AUTOSAR XML (schema 4-2-1)
package /ComponentTypes
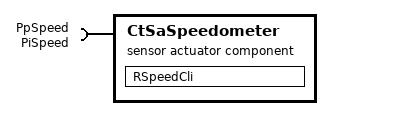
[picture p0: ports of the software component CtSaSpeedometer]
  sensor actuator sw component type CtSaSpeedometer
    require port PpSpeed: required-interface=PiSpeed
    behavior CtSaSpeedometer_InternalBehavior: data-type-mapping=ApMappingSet
      runnable RSpeedCli
        sync call SC_PpSpeed_ReadChannel: operation=PpSpeed.ReadChannel, timeout=0
  swc implementation CtSaSpeedometer_Implementation: behavior=CtSaSpeedometer_InternalBehavior
    code-descriptors:
      code Default: artifact-descriptors=autosar-engineering-object={short-label=Default, category=SWSRC}
